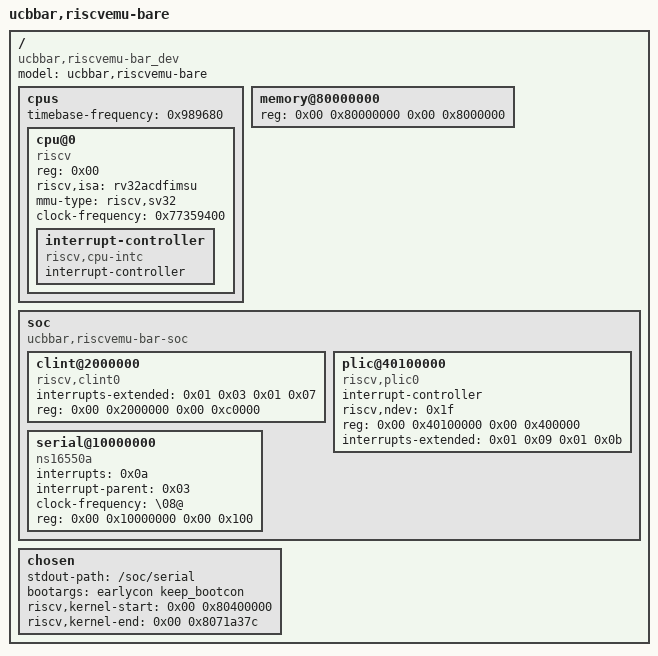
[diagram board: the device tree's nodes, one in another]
/dts-v1/;

/ {
	#address-cells = <0x02>;
	#size-cells = <0x02>;
	compatible = "ucbbar,riscvemu-bar_dev";
	model = "ucbbar,riscvemu-bare";

	cpus {
		#address-cells = <0x01>;
		#size-cells = <0x00>;
		timebase-frequency = <0x989680>;

		cpu@0 {
			device_type = "cpu";
			reg = <0x00>;
			status = "okay";
			compatible = "riscv";
			riscv,isa = "rv32acdfimsu";
			mmu-type = "riscv,sv32";
			clock-frequency = <0x77359400>;

			interrupt-controller {
				#interrupt-cells = <0x01>;
				interrupt-controller;
				compatible = "riscv,cpu-intc";
				phandle = <0x01>;
			};
		};
	};

	memory@80000000 {
		device_type = "memory";
		reg = <0x00 0x80000000 0x00 0x8000000>;
	};

	soc {
		#address-cells = <0x02>;
		#size-cells = <0x02>;
		compatible = "ucbbar,riscvemu-bar-soc\0simple-bus";
		ranges;

		clint@2000000 {
			compatible = "riscv,clint0";
			interrupts-extended = <0x01 0x03 0x01 0x07>;
			reg = <0x00 0x2000000 0x00 0xc0000>;
		};

		plic@40100000 {
			#interrupt-cells = <0x01>;
			interrupt-controller;
			compatible = "riscv,plic0";
			riscv,ndev = <0x1f>;
			reg = <0x00 0x40100000 0x00 0x400000>;
			interrupts-extended = <0x01 0x09 0x01 0x0b>;
			phandle = <0x02>;
		};

		serial@10000000 {
			interrupts = <0x0a>;
			interrupt-parent = <0x03>;
			clock-frequency = "\08@";
			reg = <0x00 0x10000000 0x00 0x100>;
			compatible = "ns16550a";
		};
	};

	chosen {
		stdout-path = "/soc/serial";
		bootargs = "earlycon keep_bootcon";
		riscv,kernel-start = <0x00 0x80400000>;
		riscv,kernel-end = <0x00 0x8071a37c>;
	};
};
